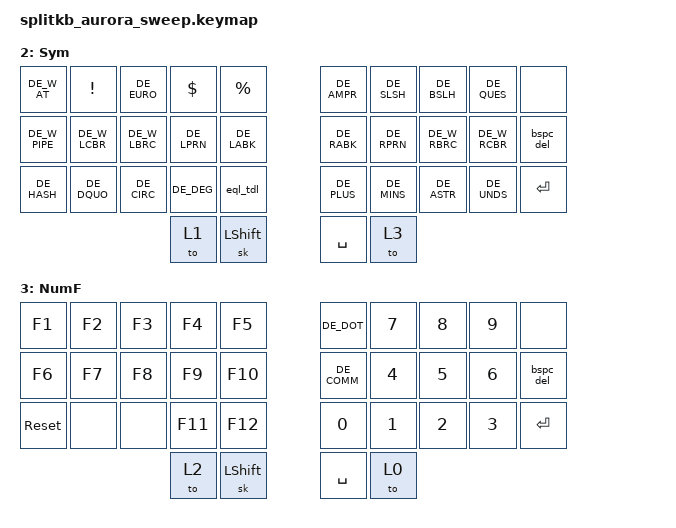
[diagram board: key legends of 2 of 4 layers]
/*
 * Copyright (c) 2022 The ZMK Contributors
 *
 * SPDX-License-Identifier: MIT
 */

#include <behaviors.dtsi>
#include <dt-bindings/zmk/keys.h>
#include <dt-bindings/zmk/bt.h>
#include <dt-bindings/zmk/outputs.h>

#include "german-keymap.h"

#define BASE 0
#define UMFCTN 1
#define SYM 2
#define NUMF 3

#define MO_TOG(layer) &mo_tog layer layer   // Macro to apply momentary-layer-on-hold/toggle-layer-on-tap to a specific layer

#define HRML(k2,k3,k4) &ht LCTRL k2  &ht LGUI k3  &ht LALT k4
#define HRMR(k1,k2,k3) &ht RALT k1  &ht RGUI k2  &ht RCTRL k3



&mt {
  //  flavor = "tap-preferred";
   // tapping_term_ms = <200>;
};

&sk {
    release-after-ms = <2000>;
    quick-release;
    /delete-property/ ignore-modifiers;
};

/ {

    combos {
        compatible = "zmk,combos";
        
        combo_esc {
            timeout-ms = <50>;
            key-positions = <1 2>;
            bindings = <&kp ESC>;
        };

        combo_tab {
            timeout-ms = <50>;
            key-positions = <21 22>;
            bindings = <&kp TAB>;
        };

        caps_lock {
            timeout-ms = <50>;
            key-positions = <31 32>;
            bindings = <&kp CAPSLOCK>;
        };

        Layer_default {
            timeout-ms = <50>;
            key-positions = <30 33>;
            bindings = <&to 0>;
        };        



    // END COMBOS
    };

    behaviors {

        ht: hold_tap {
            compatible = "zmk,behavior-hold-tap";
            label = "hold_tap";
            #binding-cells = <2>;
            flavor = "tap-preferred";
            tapping-term-ms = <220>;
            quick-tap-ms = <150>;
            global-quick-tap;
            bindings = <&kp>, <&kp>;
        };

        bspc_del: bspc_del {
            compatible = "zmk,behavior-mod-morph";
            label = "BACKSPACE_TO_DELETE";
            #binding-cells = <0>;
            bindings = <&kp BSPC>, <&kp DEL>;
            mods = <(MOD_LSFT|MOD_RSFT)>;
        };

        cma_scln: cma_scln {
            compatible = "zmk,behavior-mod-morph";
            label = "cma_to_scln";
            #binding-cells = <0>;
            bindings = <&kp DE_COMM>, <&kp DE_SCLN>;
            mods = <(MOD_LSFT|MOD_RSFT)>;
        };

        dot_cln: dot_cln {
            compatible = "zmk,behavior-mod-morph";
            label = "dot_to_cln";
            #binding-cells = <0>;
            bindings = <&kp DE_DOT>, <&kp DE_COLN>;
            mods = <(MOD_LSFT|MOD_RSFT)>;
        };

        mo_tog: behavior_mo_tog {
            compatible = "zmk,behavior-hold-tap";
            label = "mo_tog";
            #binding-cells = <2>;
            flavor = "hold-preferred";
            tapping-term-ms = <200>;
            bindings = <&mo>, <&tog>;
        };

        eql_tdl: eql_tdl {
            compatible = "zmk,behavior-mod-morph";
            label = "equal_to_tilde";
            #binding-cells = <0>;
            bindings = <&kp DE_EQL>, <&kp DE_W_TILD>;
            mods = <(MOD_LSFT|MOD_RSFT)>;
        };


        

    // END BEHAVIORS
    };


    /*                              34 KEY MATRIX / LAYOUT MAPPING

    ╭────────────────────┬────────────────────╮ ╭─────────────────────┬─────────────────────╮
    │  0   1   2   3   4 │  5   6   7   8   9 │ │ LT4 LT3 LT2 LT1 LT0 │ RT0 RT1 RT2 RT3 RT4 │
    │ 10  11  12  13  14 │ 15  16  17  18  19 │ │ LM4 LM3 LM2 LM1 LM0 │ RM0 RM1 RM2 RM3 RM4 │
    │ 20  21  22  23  24 │ 25  26  27  28  29 │ │ LB4 LB3 LB2 LB1 LB0 │ RB0 RB1 RB2 RB3 RB4 │
    ╰───────────╮ 30  31 │ 32  33 ╭───────────╯ ╰───────────╮ LH1 LH0 │ RH0 RH1 ╭───────────╯
                ╰────────┴────────╯                         ╰─────────┴─────────╯              */


    keymap {
        compatible = "zmk,keymap";

        layer_0 {
            label = "Base";
            bindings = <
        //╭─────────────┬─────────────┬─────────────┬─────────────┬─────────────╮   ╭─────────────┬─────────────┬─────────────┬─────────────┬─────────────╮
        //│ Q           │ W           │ E           │ R           │ T           │   │ Z           │ U           │ I           │ O           │ P           │
            &kp Q         &kp W         &kp E         &kp R         &kp T             &kp Y         &kp U         &kp I         &kp O         &kp P
        //├─────────────┼─────────────┼─────────────┼─────────────┼─────────────┤   ├─────────────┼─────────────┼─────────────┼─────────────┼─────────────┤
        //│ A           │ S           │ D           │ F           │ G           │   │ H           │ J           │ K           │ L           │ BSPC DEL    │
            &kp A         HRML(S,       D,            F)            &kp G             &kp H         HRMR(J,       K,            L)            &bspc_del
        //├─────────────┼─────────────┼─────────────┼─────────────┼─────────────┤   ├─────────────┼─────────────┼─────────────┼─────────────┼─────────────┤
        //│ Y           │ X           │ C           │ V           │ B           │   │ N           │ M           │ , ;         │ . ;         │ ENTER       │
            &kp Z         &kp X         &kp C         &kp V         &kp B             &kp N         &kp M         &cma_scln     &dot_cln      &kp ENTER
        //├─────────────┼─────────────┼─────────────┼─────────────┼─────────────┤   ├─────────────┼─────────────┼─────────────┼─────────────┼─────────────┤
        //│                                         │ THUMB 2     │ THUMB 1     │   │ THUMB 1     │ THUMB 2     │ 
                                                      &sl 1         &sk LSHIFT        &kp SPACE     &to 1
        //                                          ╰─────────────┴─────────────╯   ╰─────────────┴─────────────╯
            >;  
        };


        layer_1 {
            label = "UmFct";
            bindings = <
        //╭─────────────┬─────────────┬─────────────┬─────────────┬─────────────╮   ╭─────────────┬─────────────┬─────────────┬─────────────┬─────────────╮
        //│ none        │ none        │ Mute        │ Vol Down    │ Vol Up      │   │ ScrShot     │ Ü           │ Arrow Up    │ Ö           │ Apostroph   │
            &none         &none         &kp C_MUTE    &kp C_VOL_DN  &kp C_VOL_UP      &kp PSCRN     &kp DE_UE     &kp UP        &kp DE_OE     &kp DE_QUOT
        //├─────────────┼─────────────┼─────────────┼─────────────┼─────────────┤   ├─────────────┼─────────────┼─────────────┼─────────────┼─────────────┤
        //│ Ä           │ ß           │ Previous    │ Play Pause  │ Next        │   │ Home        │ Arrow right │ Arrow down  │ Arrow right │ BSPC DEL    │
            &kp DE_AE     HRML(DE_SS,   C_PREV,       C_PLAY_PAUSE)  &kp C_NEXT       &kp HOME      &kp LEFT      &kp DOWN      &kp RIGHT     &bspc_del
        //├─────────────┼─────────────┼─────────────┼─────────────┼─────────────┤   ├─────────────┼─────────────┼─────────────┼─────────────┼─────────────┤
        //│ Next BLE    │ Previous BLE│ Clear BLE   │ Out BLE     │ Out USB     │   │ End         │ none        │ none        │ →           │ ENTER       │
            &bt BT_NXT    &bt BT_PRV    &bt BT_CLR    &out OUT_BLE  &out OUT_USB      &kp END       &none         &none         &none         &kp ENTER
        //├─────────────┼─────────────┼─────────────┼─────────────┼─────────────┤   ├─────────────┼─────────────┼─────────────┼─────────────┼─────────────┤
        //│                                         │ THUMB 2     │ THUMB 1     │   │ THUMB 1     │ THUMB 2     │ 
                                                      &to 0         &sk LSHIFT        &kp SPACE     &to 2
        //                                          ╰─────────────┴─────────────╯   ╰─────────────┴─────────────╯
            >;
        };


        layer_2 {
            label = "Sym";
            bindings = <
        //╭─────────────┬─────────────┬─────────────┬─────────────┬─────────────╮   ╭─────────────┬─────────────┬─────────────┬─────────────┬─────────────╮
        //│ @           │ !           │ €           │ $           │ %           │   │ &           │ /           │ \           │ ?           │ ´`          │
            &kp DE_W_AT   &kp EXCL      &kp DE_EURO   &kp DLLR      &kp PRCNT         &kp DE_AMPR   &kp DE_SLSH   &kp DE_BSLH   &kp DE_QUES   &none
        //├─────────────┼─────────────┼─────────────┼─────────────┼─────────────┤   ├─────────────┼─────────────┼─────────────┼─────────────┼─────────────┤
        //│ |           │ {           │ [           │ (           │ <           │   │ >           │ )           │ ]           │ }           │ BSPC DEL    │
          &kp DE_W_PIPE  &kp DE_W_LCBR  &kp DE_W_LBRC  &kp DE_LPRN  &kp DE_LABK       &kp DE_RABK   &kp DE_RPRN  &kp DE_W_RBRC  &kp DE_W_RCBR  &bspc_del
        //├─────────────┼─────────────┼─────────────┼─────────────┼─────────────┤   ├─────────────┼─────────────┼─────────────┼─────────────┼─────────────┤
        //│ #           │ "           │ ^           │ °           │ =~          │   │ +           │ - –         │ *           │ _           │ ENTER       │
            &kp DE_HASH   &kp DE_DQUO   &kp DE_CIRC   &kp DE_DEG    &eql_tdl          &kp DE_PLUS   &kp DE_MINS   &kp DE_ASTR   &kp DE_UNDS   &kp ENTER
        //├─────────────┼─────────────┼─────────────┼─────────────┼─────────────┤   ├─────────────┼─────────────┼─────────────┼─────────────┼─────────────┤
        //│                                         │ THUMB 2     │ THUMB 1     │   │ THUMB 1     │ THUMB 2     │ 
                                                      &to 1         &sk LSHIFT        &kp SPACE     &to 3
        //                                          ╰─────────────┴─────────────╯   ╰─────────────┴─────────────╯
            >;  
        };

        layer_3 {
            label = "NumF";
            bindings = <
        //╭─────────────┬─────────────┬─────────────┬─────────────┬─────────────╮   ╭─────────────┬─────────────┬─────────────┬─────────────┬─────────────╮
        //│ F1          │ F2          │ F3          │ F4          │ F5          │   │ .           │ 7           │ 8           │ 9           │             │
            &kp F1        &kp F2        &kp F3        &kp F4        &kp F5            &kp DE_DOT    &kp N7        &kp N8        &kp N9        &none
        //├─────────────┼─────────────┼─────────────┼─────────────┼─────────────┤   ├─────────────┼─────────────┼─────────────┼─────────────┼─────────────┤
        //│ F6          │ F7          │ F8          │ F9          │ F10         │   │ ,           │ 4           │ 5           │ 6           │ BSPC DEL    │
            &kp F6        &kp F7        &kp F8        &kp F9        &kp F10           &kp DE_COMM   &kp N4        &kp N5        &kp N6        &bspc_del
        //├─────────────┼─────────────┼─────────────┼─────────────┼─────────────┤   ├─────────────┼─────────────┼─────────────┼─────────────┼─────────────┤
        //│ none        │ none        │ none        │ F11         │ F12         │   │ 0           │ 1           │ 2           │ 3           │ ENTER       │
            &sys_reset    &none         &none         &kp F11       &kp F12           &kp N0        &kp N1        &kp N2        &kp N3        &kp ENTER
        //├─────────────┼─────────────┼─────────────┼─────────────┼─────────────┤   ├─────────────┼─────────────┼─────────────┼─────────────┼─────────────┤
        //│                                         │ THUMB 2     │ THUMB 1     │   │ THUMB 1     │ THUMB 2     │ 
                                                      &to 2         &sk LSHIFT        &kp SPACE     &to 0
        //                                          ╰─────────────┴─────────────╯   ╰─────────────┴─────────────╯
            >;  
        };









    // END KEYMAP
    };
};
